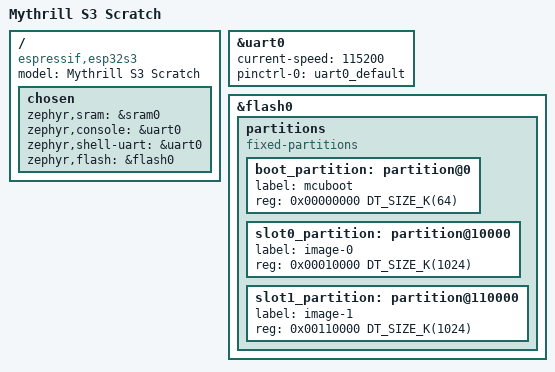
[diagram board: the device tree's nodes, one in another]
/dts-v1/;
#include <espressif/esp32s3/esp32s3_wroom_n8.dtsi>
#include "mythrill_s3_scratch-pinctrl.dtsi"

/ {
        model = "Mythrill S3 Scratch";
        compatible = "espressif,esp32s3";

        chosen {
                zephyr,sram = &sram0;
                zephyr,console = &uart0;
                zephyr,shell-uart = &uart0;
                zephyr,flash = &flash0;
        };
};

&uart0 {
        status = "okay";
        current-speed = <115200>;
        pinctrl-0 = <&uart0_default>;
        pinctrl-names = "default";
};

&flash0 {
    partitions {
        compatible = "fixed-partitions";
        #address-cells = <1>;
        #size-cells = <1>;

        boot_partition: partition@0 {
            label = "mcuboot";
            reg = <0x00000000 DT_SIZE_K(64)>;
        };

        slot0_partition: partition@10000 {
            label = "image-0";
            reg = <0x00010000 DT_SIZE_K(1024)>;
        };

        slot1_partition: partition@110000 {
            label = "image-1";
            reg = <0x00110000 DT_SIZE_K(1024)>;
        };
    };
};
